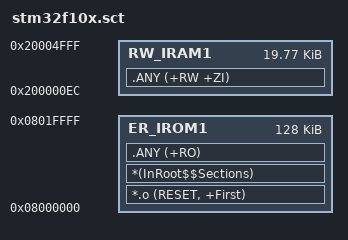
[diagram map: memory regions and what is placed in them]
; *************************************************************
; *** Scatter-Loading Description File generated by uVision ***
; *************************************************************

LR_IROM1 0x08000000 0x20000  {    ; load region size_region (128K)

  ER_IROM1 0x08000000 0x20000  {  ; load address = execution address
   *.o (RESET, +First)
   *(InRoot$$Sections)
   .ANY (+RO)
  }

  ; 59 vectors (16 core + 43 peripheral) * 4 bytes = 236 bytes to reserve (0xEC)
  RW_IRAM1 (0x20000000+0xEC) (0x5000-0xEC)  {  ; RW data
   .ANY (+RW +ZI)
  }

}

